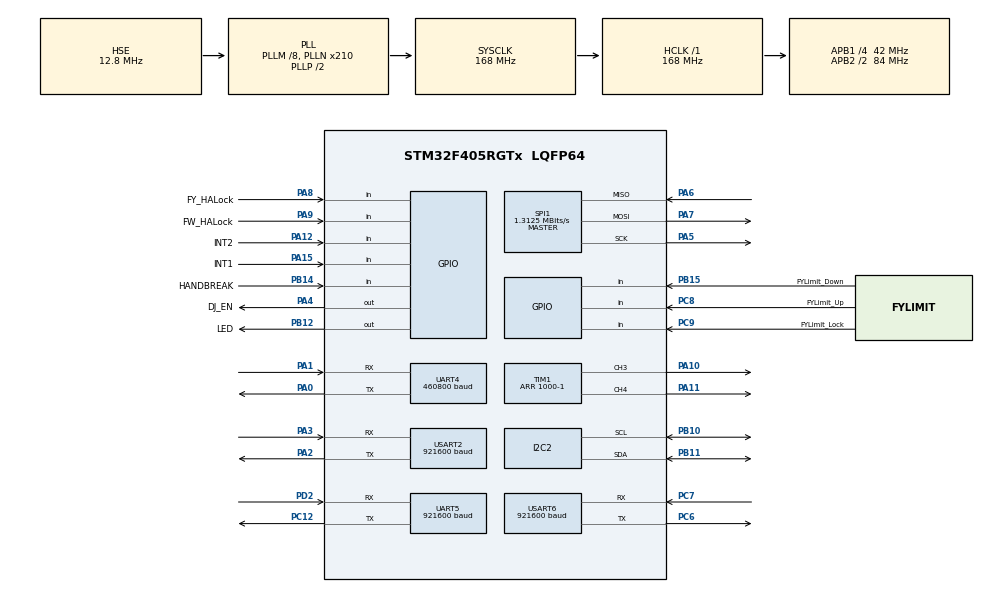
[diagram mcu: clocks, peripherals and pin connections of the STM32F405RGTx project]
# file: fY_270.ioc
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Dma.Request0=USART2_RX
Dma.Request1=USART2_TX
Dma.Request2=UART4_RX
Dma.Request3=UART4_TX
Dma.Request4=SPI1_RX
Dma.Request5=SPI1_TX
Dma.Request6=USART6_RX
Dma.Request7=USART6_TX
Dma.Request8=UART5_RX
Dma.Request9=UART5_TX
Dma.SPI1_RX.4.Direction=DMA_PERIPH_TO_MEMORY
Dma.SPI1_RX.4.FIFOMode=DMA_FIFOMODE_DISABLE
Dma.SPI1_RX.4.Instance=DMA2_Stream0
Dma.SPI1_RX.4.MemDataAlignment=DMA_MDATAALIGN_BYTE
Dma.SPI1_RX.4.MemInc=DMA_MINC_ENABLE
Dma.SPI1_RX.4.Mode=DMA_NORMAL
Dma.SPI1_RX.4.PeriphDataAlignment=DMA_PDATAALIGN_BYTE
Dma.SPI1_RX.4.PeriphInc=DMA_PINC_DISABLE
Dma.SPI1_RX.4.Priority=DMA_PRIORITY_LOW
Dma.SPI1_TX.5.Direction=DMA_MEMORY_TO_PERIPH
Dma.SPI1_TX.5.FIFOMode=DMA_FIFOMODE_DISABLE
Dma.SPI1_TX.5.Instance=DMA2_Stream3
Dma.SPI1_TX.5.MemDataAlignment=DMA_MDATAALIGN_BYTE
Dma.SPI1_TX.5.MemInc=DMA_MINC_ENABLE
Dma.SPI1_TX.5.Mode=DMA_NORMAL
Dma.SPI1_TX.5.PeriphDataAlignment=DMA_PDATAALIGN_BYTE
Dma.SPI1_TX.5.PeriphInc=DMA_PINC_DISABLE
Dma.SPI1_TX.5.Priority=DMA_PRIORITY_LOW
Dma.UART4_RX.2.Direction=DMA_PERIPH_TO_MEMORY
Dma.UART4_RX.2.FIFOMode=DMA_FIFOMODE_DISABLE
Dma.UART4_RX.2.Instance=DMA1_Stream2
Dma.UART4_RX.2.MemDataAlignment=DMA_MDATAALIGN_BYTE
Dma.UART4_RX.2.MemInc=DMA_MINC_ENABLE
Dma.UART4_RX.2.Mode=DMA_CIRCULAR
Dma.UART4_RX.2.PeriphDataAlignment=DMA_PDATAALIGN_BYTE
Dma.UART4_RX.2.PeriphInc=DMA_PINC_DISABLE
Dma.UART4_RX.2.Priority=DMA_PRIORITY_LOW
Dma.UART4_TX.3.Direction=DMA_MEMORY_TO_PERIPH
Dma.UART4_TX.3.FIFOMode=DMA_FIFOMODE_DISABLE
Dma.UART4_TX.3.Instance=DMA1_Stream4
Dma.UART4_TX.3.MemDataAlignment=DMA_MDATAALIGN_BYTE
Dma.UART4_TX.3.MemInc=DMA_MINC_ENABLE
Dma.UART4_TX.3.Mode=DMA_NORMAL
Dma.UART4_TX.3.PeriphDataAlignment=DMA_PDATAALIGN_BYTE
Dma.UART4_TX.3.PeriphInc=DMA_PINC_DISABLE
Dma.UART4_TX.3.Priority=DMA_PRIORITY_LOW
Dma.UART5_RX.8.Direction=DMA_PERIPH_TO_MEMORY
Dma.UART5_RX.8.FIFOMode=DMA_FIFOMODE_DISABLE
Dma.UART5_RX.8.Instance=DMA1_Stream0
Dma.UART5_RX.8.MemDataAlignment=DMA_MDATAALIGN_BYTE
Dma.UART5_RX.8.MemInc=DMA_MINC_ENABLE
Dma.UART5_RX.8.Mode=DMA_CIRCULAR
Dma.UART5_RX.8.PeriphDataAlignment=DMA_PDATAALIGN_BYTE
Dma.UART5_RX.8.PeriphInc=DMA_PINC_DISABLE
Dma.UART5_RX.8.Priority=DMA_PRIORITY_LOW
Dma.UART5_TX.9.Direction=DMA_MEMORY_TO_PERIPH
Dma.UART5_TX.9.FIFOMode=DMA_FIFOMODE_DISABLE
Dma.UART5_TX.9.Instance=DMA1_Stream7
Dma.UART5_TX.9.MemDataAlignment=DMA_MDATAALIGN_BYTE
Dma.UART5_TX.9.MemInc=DMA_MINC_ENABLE
Dma.UART5_TX.9.Mode=DMA_NORMAL
Dma.UART5_TX.9.PeriphDataAlignment=DMA_PDATAALIGN_BYTE
Dma.UART5_TX.9.PeriphInc=DMA_PINC_DISABLE
Dma.UART5_TX.9.Priority=DMA_PRIORITY_LOW
Dma.USART2_RX.0.Direction=DMA_PERIPH_TO_MEMORY
Dma.USART2_RX.0.FIFOMode=DMA_FIFOMODE_DISABLE
Dma.USART2_RX.0.Instance=DMA1_Stream5
Dma.USART2_RX.0.MemDataAlignment=DMA_MDATAALIGN_BYTE
Dma.USART2_RX.0.MemInc=DMA_MINC_ENABLE
Dma.USART2_RX.0.Mode=DMA_CIRCULAR
Dma.USART2_RX.0.PeriphDataAlignment=DMA_PDATAALIGN_BYTE
Dma.USART2_RX.0.PeriphInc=DMA_PINC_DISABLE
Dma.USART2_RX.0.Priority=DMA_PRIORITY_LOW
Dma.USART2_TX.1.Direction=DMA_MEMORY_TO_PERIPH
Dma.USART2_TX.1.FIFOMode=DMA_FIFOMODE_DISABLE
Dma.USART2_TX.1.Instance=DMA1_Stream6
Dma.USART2_TX.1.MemDataAlignment=DMA_MDATAALIGN_BYTE
Dma.USART2_TX.1.MemInc=DMA_MINC_ENABLE
Dma.USART2_TX.1.Mode=DMA_NORMAL
Dma.USART2_TX.1.PeriphDataAlignment=DMA_PDATAALIGN_BYTE
Dma.USART2_TX.1.PeriphInc=DMA_PINC_DISABLE
Dma.USART2_TX.1.Priority=DMA_PRIORITY_LOW
Dma.USART6_RX.6.Direction=DMA_PERIPH_TO_MEMORY
Dma.USART6_RX.6.FIFOMode=DMA_FIFOMODE_DISABLE
Dma.USART6_RX.6.Instance=DMA2_Stream1
Dma.USART6_RX.6.MemDataAlignment=DMA_MDATAALIGN_BYTE
Dma.USART6_RX.6.MemInc=DMA_MINC_ENABLE
Dma.USART6_RX.6.Mode=DMA_CIRCULAR
Dma.USART6_RX.6.PeriphDataAlignment=DMA_PDATAALIGN_BYTE
Dma.USART6_RX.6.PeriphInc=DMA_PINC_DISABLE
Dma.USART6_RX.6.Priority=DMA_PRIORITY_LOW
Dma.USART6_TX.7.Direction=DMA_MEMORY_TO_PERIPH
Dma.USART6_TX.7.FIFOMode=DMA_FIFOMODE_DISABLE
Dma.USART6_TX.7.Instance=DMA2_Stream6
Dma.USART6_TX.7.MemDataAlignment=DMA_MDATAALIGN_BYTE
Dma.USART6_TX.7.MemInc=DMA_MINC_ENABLE
Dma.USART6_TX.7.Mode=DMA_NORMAL
Dma.USART6_TX.7.PeriphDataAlignment=DMA_PDATAALIGN_BYTE
Dma.USART6_TX.7.PeriphInc=DMA_PINC_DISABLE
Dma.USART6_TX.7.Priority=DMA_PRIORITY_LOW
Mcu.Family=STM32F4
Mcu.Name=STM32F405RGTx
Mcu.Package=LQFP64
NVIC.DMA1_Stream0_IRQn=true\:0\:0\:false\:false\:true\:false\:true\:true
NVIC.DMA1_Stream2_IRQn=true\:0\:0\:false\:false\:true\:false\:true\:true
NVIC.DMA1_Stream4_IRQn=true\:0\:0\:false\:false\:true\:false\:true\:true
NVIC.DMA1_Stream5_IRQn=true\:0\:0\:false\:false\:true\:false\:true\:true
NVIC.DMA1_Stream6_IRQn=true\:0\:0\:false\:false\:true\:false\:true\:true
NVIC.DMA1_Stream7_IRQn=true\:0\:0\:false\:false\:true\:false\:true\:true
NVIC.DMA2_Stream0_IRQn=true\:0\:0\:false\:false\:true\:false\:true\:true
NVIC.DMA2_Stream1_IRQn=true\:0\:0\:false\:false\:true\:false\:true\:true
NVIC.DMA2_Stream3_IRQn=true\:0\:0\:false\:false\:true\:false\:true\:true
NVIC.DMA2_Stream6_IRQn=true\:0\:0\:false\:false\:true\:false\:true\:true
NVIC.I2C2_ER_IRQn=true\:0\:0\:false\:false\:true\:true\:true\:true
NVIC.I2C2_EV_IRQn=true\:0\:0\:false\:false\:true\:true\:true\:true
NVIC.PriorityGroup=NVIC_PRIORITYGROUP_4
NVIC.SPI1_IRQn=true\:0\:0\:false\:false\:true\:true\:true\:true
NVIC.TIM6_DAC_IRQn=true\:0\:0\:false\:false\:true\:true\:true\:true
NVIC.UART4_IRQn=true\:0\:0\:false\:false\:true\:true\:true\:true
NVIC.UART5_IRQn=true\:0\:0\:false\:false\:true\:true\:true\:true
NVIC.USART2_IRQn=true\:0\:0\:false\:false\:true\:true\:true\:true
NVIC.USART6_IRQn=true\:0\:0\:false\:false\:true\:true\:true\:true
PA0-WKUP.Mode=Asynchronous
PA0-WKUP.Signal=UART4_TX
PA1.Mode=Asynchronous
PA1.Signal=UART4_RX
PA10.Signal=S_TIM1_CH3
PA11.Signal=S_TIM1_CH4
PA12.GPIO_Label=INT2
PA12.Signal=GPIO_Input
PA13.Mode=Trace_Asynchronous_SW
PA13.Signal=SYS_JTMS-SWDIO
PA14.Mode=Trace_Asynchronous_SW
PA14.Signal=SYS_JTCK-SWCLK
PA15.GPIO_Label=INT1
PA15.Signal=GPIO_Input
PA2.Mode=Asynchronous
PA2.Signal=USART2_TX
PA3.Mode=Asynchronous
PA3.Signal=USART2_RX
PA4.GPIO_Label=DJ_EN
PA4.GPIO_PuPd=GPIO_PULLDOWN
PA4.Signal=GPIO_Output
PA5.Mode=Full_Duplex_Master
PA5.Signal=SPI1_SCK
PA6.Mode=Full_Duplex_Master
PA6.Signal=SPI1_MISO
PA7.Mode=Full_Duplex_Master
PA7.Signal=SPI1_MOSI
PA8.GPIO_Label=FY_HALock
PA8.Signal=GPIO_Input
PA9.GPIO_Label=FW_HALock
PA9.Signal=GPIO_Input
PB10.Mode=I2C
PB10.Signal=I2C2_SCL
PB11.Mode=I2C
PB11.Signal=I2C2_SDA
PB12.GPIO_Label=LED
PB12.Signal=GPIO_Output
PB14.GPIO_Label=HANDBREAK
PB14.Signal=GPIO_Input
PB15.GPIO_Label=FYLimit_Down
PB15.Signal=GPIO_Input
PB3.Mode=Trace_Asynchronous_SW
PB3.Signal=SYS_JTDO-SWO
PC12.Mode=Asynchronous
PC12.Signal=UART5_TX
PC6.Mode=Asynchronous
PC6.Signal=USART6_TX
PC7.Mode=Asynchronous
PC7.Signal=USART6_RX
PC8.GPIO_Label=FYLimit_Up
PC8.Signal=GPIO_Input
PC9.GPIO_Label=FYLimit_Lock
PC9.Signal=GPIO_Input
PD2.Mode=Asynchronous
PD2.Signal=UART5_RX
PH0-OSC_IN.Mode=HSE-External-Oscillator
PH0-OSC_IN.Signal=RCC_OSC_IN
PH1-OSC_OUT.Mode=HSE-External-Oscillator
PH1-OSC_OUT.Signal=RCC_OSC_OUT
ProjectManager.HeapSize=0x200
ProjectManager.StackSize=0x400
ProjectManager.TargetToolchain=MDK-ARM V5.32
RCC.48MHZClocksFreq_Value=84000000
RCC.AHBFreq_Value=168000000
RCC.APB1CLKDivider=RCC_HCLK_DIV4
RCC.APB1Freq_Value=42000000
RCC.APB1TimFreq_Value=84000000
RCC.APB2CLKDivider=RCC_HCLK_DIV2
RCC.APB2Freq_Value=84000000
RCC.APB2TimFreq_Value=168000000
RCC.CortexFreq_Value=168000000
RCC.HCLKFreq_Value=168000000
RCC.HSE_VALUE=12800000
RCC.HSI_VALUE=16000000
RCC.LSE_VALUE=32768
RCC.PLLM=8
RCC.PLLN=210
RCC.PLLSourceVirtual=RCC_PLLSOURCE_HSE
RCC.SYSCLKFreq_VALUE=168000000
RCC.SYSCLKSource=RCC_SYSCLKSOURCE_PLLCLK
RCC.VCOOutputFreq_Value=336000000
SH.S_TIM1_CH3.0=TIM1_CH3,PWM Generation3 CH3
SH.S_TIM1_CH4.0=TIM1_CH4,PWM Generation4 CH4
SPI1.BaudRatePrescaler=SPI_BAUDRATEPRESCALER_64
SPI1.CLKPhase=SPI_PHASE_2EDGE
SPI1.CLKPolarity=SPI_POLARITY_HIGH
SPI1.CalculateBaudRate=1.3125 MBits/s
SPI1.Direction=SPI_DIRECTION_2LINES
SPI1.Mode=SPI_MODE_MASTER
SPI1.VirtualType=VM_MASTER
TIM1.Channel-PWM\ Generation3\ CH3=TIM_CHANNEL_3
TIM1.Channel-PWM\ Generation4\ CH4=TIM_CHANNEL_4
TIM1.Period=1000-1
TIM6.Period=10-1
TIM6.Prescaler=8400-1
UART4.BaudRate=460800
UART4.VirtualMode=Asynchronous
UART5.BaudRate=921600
UART5.VirtualMode=Asynchronous
USART2.BaudRate=921600
USART2.VirtualMode=VM_ASYNC
USART6.BaudRate=921600
USART6.VirtualMode=VM_ASYNC
VP_TIM1_VS_ClockSourceINT.Mode=Internal
VP_TIM6_VS_ClockSourceINT.Mode=Enable_Timer
board=custom

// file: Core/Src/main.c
/* USER CODE BEGIN Header */
/**
  ******************************************************************************
  * @file           : main.c
  * @brief          : Main program body
  ******************************************************************************
  * @attention
  *
  * Copyright (c) 2026 STMicroelectronics.
  * All rights reserved.
  *
  * This software is licensed under terms that can be found in the LICENSE file
  * in the root directory of this software component.
  * If no LICENSE file comes with this software, it is provided AS-IS.
  *
  ******************************************************************************
  */
  /*************************
  俯仰锁已解决
  俯仰到方位要发计算后的值
  用内部值去判断上锁的范围

  可用版本，修复了使用发往图像版的值来判断的问题，将方位值解算后发往方位
  ************************/
/* USER CODE END Header */
#include "main.h"
#include "dma.h"
#include "i2c.h"
#include "spi.h"
#include "tim.h"
#include "usart.h"
#include "gpio.h"

/* USER CODE BEGIN Includes */
#include "APP/app/app_ctrl.h"
#include "SF.h"
/* USER CODE END Includes */

void SystemClock_Config(void);

int main(void)
{

  /* MCU Configuration--------------------------------------------------------*/

  /* Reset of all peripherals, Initializes the Flash interface and the Systick. */
  HAL_Init();

  /* Configure the system clock */
  SystemClock_Config();
  /* Initialize all configured peripherals */
  MX_GPIO_Init();
  MX_DMA_Init();
  MX_USART2_UART_Init();
  MX_UART4_Init();
  MX_SPI1_Init();
  MX_I2C2_Init();
  MX_USART6_UART_Init();
  MX_UART5_Init();
  MX_TIM6_Init();
  MX_TIM1_Init();
  /* USER CODE BEGIN 2 */
	APP_Ctrl_System_Init();
  /* USER CODE END 2 */
  /* Infinite loop */
  /* USER CODE BEGIN WHILE */
  while (1)
  {
	  APP_Ctrl_System_Handle();
    /* USER CODE END WHILE */
  }
}

void SystemClock_Config(void)
{
  RCC_OscInitTypeDef RCC_OscInitStruct = {0};
  RCC_ClkInitTypeDef RCC_ClkInitStruct = {0};

  /** Configure the main internal regulator output voltage
  */
  __HAL_RCC_PWR_CLK_ENABLE();
  __HAL_PWR_VOLTAGESCALING_CONFIG(PWR_REGULATOR_VOLTAGE_SCALE1);

  /** Initializes the RCC Oscillators according to the specified parameters
  * in the RCC_OscInitTypeDef structure.
  */
  RCC_OscInitStruct.OscillatorType = RCC_OSCILLATORTYPE_HSE;
  RCC_OscInitStruct.HSEState = RCC_HSE_ON;
  RCC_OscInitStruct.PLL.PLLState = RCC_PLL_ON;
  RCC_OscInitStruct.PLL.PLLSource = RCC_PLLSOURCE_HSE;
  RCC_OscInitStruct.PLL.PLLM = 8;
  RCC_OscInitStruct.PLL.PLLN = 210;
  RCC_OscInitStruct.PLL.PLLP = RCC_PLLP_DIV2;
  RCC_OscInitStruct.PLL.PLLQ = 4;
  if (HAL_RCC_OscConfig(&RCC_OscInitStruct) != HAL_OK)
  {
    Error_Handler();
  }

  /** Initializes the CPU, AHB and APB buses clocks
  */
  RCC_ClkInitStruct.ClockType = RCC_CLOCKTYPE_HCLK|RCC_CLOCKTYPE_SYSCLK
                              |RCC_CLOCKTYPE_PCLK1|RCC_CLOCKTYPE_PCLK2;
  RCC_ClkInitStruct.SYSCLKSource = RCC_SYSCLKSOURCE_PLLCLK;
  RCC_ClkInitStruct.AHBCLKDivider = RCC_SYSCLK_DIV1;
  RCC_ClkInitStruct.APB1CLKDivider = RCC_HCLK_DIV4;
  RCC_ClkInitStruct.APB2CLKDivider = RCC_HCLK_DIV2;

  if (HAL_RCC_ClockConfig(&RCC_ClkInitStruct, FLASH_LATENCY_5) != HAL_OK)
  {
    Error_Handler();
  }
}
//void SystemClock_Config(void)
//{
//  RCC_OscInitTypeDef RCC_OscInitStruct = {0};
//  RCC_ClkInitTypeDef RCC_ClkInitStruct = {0};

//  /** Configure the main internal regulator output voltage
//  */
//  __HAL_RCC_PWR_CLK_ENABLE();
//  __HAL_PWR_VOLTAGESCALING_CONFIG(PWR_REGULATOR_VOLTAGE_SCALE1);

//  /** Initializes the RCC Oscillators according to the specified parameters
//  * in the RCC_OscInitTypeDef structure.
//  */
//  RCC_OscInitStruct.OscillatorType = RCC_OSCILLATORTYPE_HSE;
//  RCC_OscInitStruct.HSEState = RCC_HSE_ON;
//  RCC_OscInitStruct.PLL.PLLState = RCC_PLL_ON;
//  RCC_OscInitStruct.PLL.PLLSource = RCC_PLLSOURCE_HSE;
//  RCC_OscInitStruct.PLL.PLLM = 4;
//  RCC_OscInitStruct.PLL.PLLN = 168;
//  RCC_OscInitStruct.PLL.PLLP = RCC_PLLP_DIV2;
//  RCC_OscInitStruct.PLL.PLLQ = 4;
//  if (HAL_RCC_OscConfig(&RCC_OscInitStruct) != HAL_OK)
//  {
//    Error_Handler();
//  }

//  /** Initializes the CPU, AHB and APB buses clocks
//  */
//  RCC_ClkInitStruct.ClockType = RCC_CLOCKTYPE_HCLK|RCC_CLOCKTYPE_SYSCLK
//                              |RCC_CLOCKTYPE_PCLK1|RCC_CLOCKTYPE_PCLK2;
//  RCC_ClkInitStruct.SYSCLKSource = RCC_SYSCLKSOURCE_PLLCLK;
//  RCC_ClkInitStruct.AHBCLKDivider = RCC_SYSCLK_DIV1;
//  RCC_ClkInitStruct.APB1CLKDivider = RCC_HCLK_DIV4;
//  RCC_ClkInitStruct.APB2CLKDivider = RCC_HCLK_DIV2;

//  if (HAL_RCC_ClockConfig(&RCC_ClkInitStruct, FLASH_LATENCY_5) != HAL_OK)
//  {
//    Error_Handler();
//  }
//}

void Error_Handler(void)
{
  __disable_irq();
  while (1)
  {
  }
}
